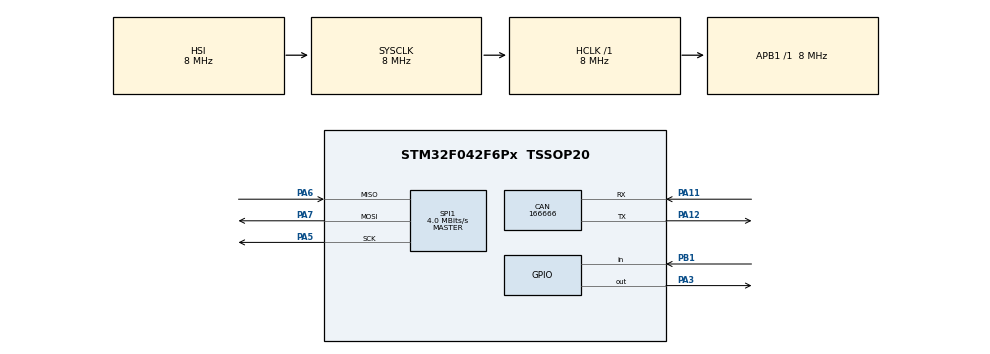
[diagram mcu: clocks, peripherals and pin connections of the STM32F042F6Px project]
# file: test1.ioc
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CAN.CalculateBaudRate=166666
CAN.CalculateTimeBit=6000
CAN.CalculateTimeQuantum=2000.0
Mcu.Family=STM32F0
Mcu.Name=STM32F042F6Px
Mcu.Package=TSSOP20
PA11.Mode=CAN_Activate
PA11.Signal=CAN_RX
PA12.Mode=CAN_Activate
PA12.Signal=CAN_TX
PA13.Mode=Serial_Wire
PA13.Signal=SYS_SWDIO
PA14.Mode=Serial_Wire
PA14.Signal=SYS_SWCLK
PA3.Signal=GPIO_Output
PA4.Signal=SPI1_NSS
PA5.Mode=Full_Duplex_Master
PA5.Signal=SPI1_SCK
PA6.Mode=Full_Duplex_Master
PA6.Signal=SPI1_MISO
PA7.Mode=Full_Duplex_Master
PA7.Signal=SPI1_MOSI
PB1.Signal=GPIO_Input
PF0-OSC_IN.Mode=HSE-External-Oscillator
PF0-OSC_IN.Signal=RCC_OSC_IN
PF1-OSC_OUT.Mode=HSE-External-Oscillator
PF1-OSC_OUT.Signal=RCC_OSC_OUT
ProjectManager.HeapSize=0x200
ProjectManager.StackSize=0x400
ProjectManager.TargetToolchain=MDK-ARM V5.32
RCC.AHBFreq_Value=8000000
RCC.APB1Freq_Value=8000000
RCC.APB1TimFreq_Value=8000000
RCC.HCLKFreq_Value=8000000
RCC.PLLMUL=RCC_PLL_MUL6
RCC.PLLSourceVirtual=RCC_PLLSOURCE_HSE
RCC.SYSCLKFreq_VALUE=8000000
SPI1.CalculateBaudRate=4.0 MBits/s
SPI1.Direction=SPI_DIRECTION_2LINES
SPI1.Mode=SPI_MODE_MASTER
SPI1.VirtualType=VM_MASTER
VP_SYS_VS_PINREMAP.Mode=PINREMAP
board=custom

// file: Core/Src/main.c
/* USER CODE BEGIN Header */
/**
  ******************************************************************************
  * @file           : main.c
  * @brief          : Main program body
  ******************************************************************************
  * @attention
  *
  * Copyright (c) 2025 STMicroelectronics.
  * All rights reserved.
  *
  * This software is licensed under terms that can be found in the LICENSE file
  * in the root directory of this software component.
  * If no LICENSE file comes with this software, it is provided AS-IS.
  *
  ******************************************************************************
  */
/* USER CODE END Header */
#include "main.h"
#include "can.h"
#include "spi.h"
#include "gpio.h"
#include "FSV9563.h"
#include "Write_DATA.h"

void SystemClock_Config(void);

int main(void)
{

  /* MCU Configuration--------------------------------------------------------*/

  /* Reset of all peripherals, Initializes the Flash interface and the Systick. */
  HAL_Init();

  /* Configure the system clock */
  SystemClock_Config();

  /* Initialize all configured peripherals */
  MX_GPIO_Init();
  MX_CAN_Init();
  MX_SPI1_Init();

  /* Infinite loop */
  /* USER CODE BEGIN WHILE */
  loadCANConfigFromFlash();
  while (1)
  {
    /* USER CODE END WHILE */
	FSV9563_ISO15693();
	if(judge(&config, &config_last) == 1)
	{
		saveCANConfigToFlash(config_last.canId, config_last.baudRate_Prescaler);
	}
  }
}

void SystemClock_Config(void)
{
  RCC_OscInitTypeDef RCC_OscInitStruct = {0};
  RCC_ClkInitTypeDef RCC_ClkInitStruct = {0};

  /** Initializes the RCC Oscillators according to the specified parameters
  * in the RCC_OscInitTypeDef structure.
  */
  RCC_OscInitStruct.OscillatorType = RCC_OSCILLATORTYPE_HSI;
  RCC_OscInitStruct.HSIState = RCC_HSI_ON;
  RCC_OscInitStruct.HSICalibrationValue = RCC_HSICALIBRATION_DEFAULT;
  RCC_OscInitStruct.PLL.PLLState = RCC_PLL_NONE;
  if (HAL_RCC_OscConfig(&RCC_OscInitStruct) != HAL_OK)
  {
    Error_Handler();
  }

  /** Initializes the CPU, AHB and APB buses clocks
  */
  RCC_ClkInitStruct.ClockType = RCC_CLOCKTYPE_HCLK|RCC_CLOCKTYPE_SYSCLK
                              |RCC_CLOCKTYPE_PCLK1;
  RCC_ClkInitStruct.SYSCLKSource = RCC_SYSCLKSOURCE_HSI;
  RCC_ClkInitStruct.AHBCLKDivider = RCC_SYSCLK_DIV1;
  RCC_ClkInitStruct.APB1CLKDivider = RCC_HCLK_DIV1;

  if (HAL_RCC_ClockConfig(&RCC_ClkInitStruct, FLASH_LATENCY_0) != HAL_OK)
  {
    Error_Handler();
  }
}

void Error_Handler(void)
{
  __disable_irq();
  while (1)
  {
  }
}
